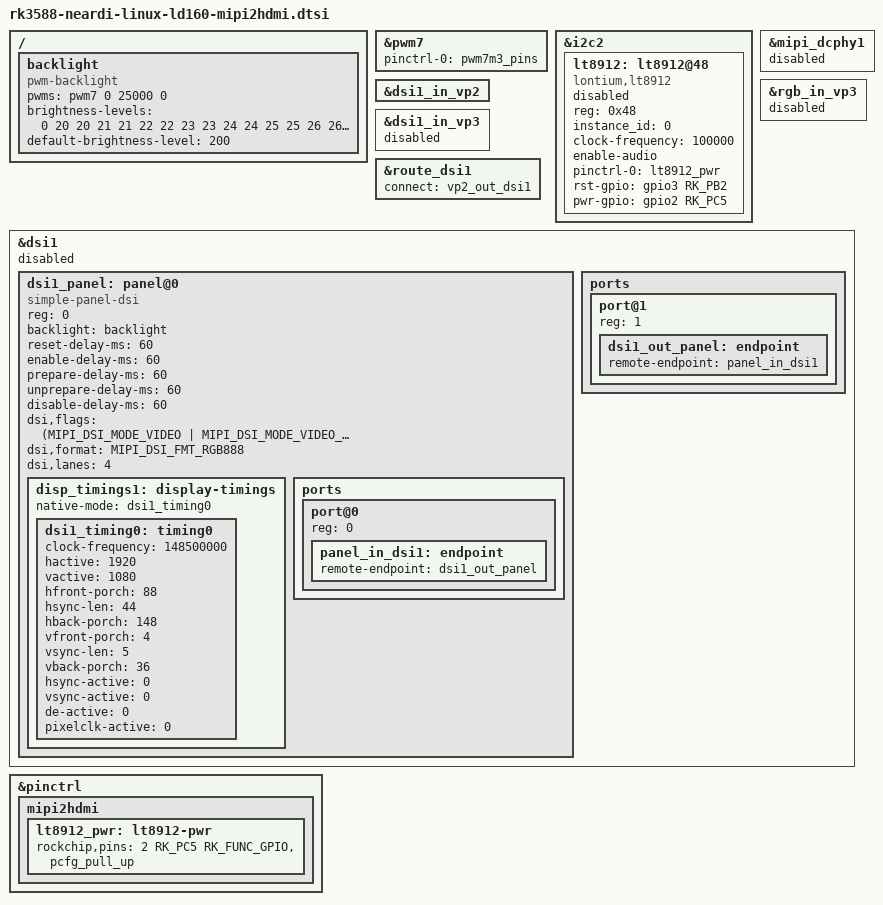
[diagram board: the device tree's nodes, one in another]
// SPDX-License-Identifier: (GPL-2.0+ OR MIT)
/*
 * Copyright (c) 2020 Rockchip Electronics Co., Ltd.
 *
 */
 
/ {
backlight: backlight {
		status="okay";
		compatible = "pwm-backlight";
		pwms = <&pwm7 0 25000 0>;
		brightness-levels = <
			  0  20  20  21  21  22  22  23
			 23  24  24  25  25  26  26  27
			 27  28  28  29  29  30  30  31
			 31  32  32  33  33  34  34  35
			 35  36  36  37  37  38  38  39
			 40  41  42  43  44  45  46  47
			 48  49  50  51  52  53  54  55
			 56  57  58  59  60  61  62  63
			 64  65  66  67  68  69  70  71
			 72  73  74  75  76  77  78  79
			 80  81  82  83  84  85  86  87
			 88  89  90  91  92  93  94  95
			 96  97  98  99 100 101 102 103
			104 105 106 107 108 109 110 111
			112 113 114 115 116 117 118 119
			120 121 122 123 124 125 126 127
			128 129 130 131 132 133 134 135
			136 137 138 139 140 141 142 143
			144 145 146 147 148 149 150 151
			152 153 154 155 156 157 158 159
			160 161 162 163 164 165 166 167
			168 169 170 171 172 173 174 175
			176 177 178 179 180 181 182 183
			184 185 186 187 188 189 190 191
			192 193 194 195 196 197 198 199
			200 201 202 203 204 205 206 207
			208 209 210 211 212 213 214 215
			216 217 218 219 220 221 222 223
			224 225 226 227 228 229 230 231
			232 233 234 235 236 237 238 239
			240 241 242 243 244 245 246 247
			248 249 250 251 252 253 254 255
		>;
		default-brightness-level = <200>;
	};

};

&pwm7{
        status = "okay";
		pinctrl-names = "active";
        pinctrl-0 = <&pwm7m3_pins>;
};

&i2c2 {
	status = "okay";
	
	lt8912:lt8912@48{
		status = "disabled";
		compatible = "lontium,lt8912";
		reg = <0x48>;
		instance_id = <0>;
		clock-frequency = <100000>;
		enable-audio;
		
		pinctrl-names = "default";
		pinctrl-0 = <&lt8912_pwr>;

		//irq-gpio = <&gpio2 RK_PC5 IRQ_TYPE_EDGE_BOTH>;
		rst-gpio = <&gpio3 RK_PB2 GPIO_ACTIVE_HIGH>; //106
		pwr-gpio = <&gpio2 RK_PC5 GPIO_ACTIVE_HIGH>; //85
	};
	};
	
	
/*
 * mipi_dcphy1 needs to be enabled
 * when dsi1 is enabled
 */
 &mipi_dcphy1{
	status = "disabled";
 };

&dsi1_in_vp2 {
	status = "okay";
};

&rgb_in_vp3{
status = "disabled";
};

&dsi1_in_vp3 {
	status = "disabled";
};


&route_dsi1 {
	status = "okay";
	connect = <&vp2_out_dsi1>;
};


&dsi1 {   
	status = "disabled";             //by lt8912 
	//force-output;
	//rockchip,lane-rate = <400>;
	dsi1_panel: panel@0 {
		status = "okay";
		compatible = "simple-panel-dsi";
		reg = <0>;
		backlight = <&backlight>;
		reset-delay-ms = <60>;
		enable-delay-ms = <60>;
		prepare-delay-ms = <60>;
		unprepare-delay-ms = <60>;
		disable-delay-ms = <60>;
		//force-output;
		dsi,flags =  <(MIPI_DSI_MODE_VIDEO | MIPI_DSI_MODE_VIDEO_BURST |
			MIPI_DSI_MODE_VIDEO_HBP | MIPI_DSI_MODE_LPM |MIPI_DSI_MODE_EOT_PACKET)>;
			
		dsi,format = <MIPI_DSI_FMT_RGB888>;
		dsi,lanes  = <4>;
		
		disp_timings1: display-timings {
			native-mode = <&dsi1_timing0>;
			dsi1_timing0: timing0 {		
			//720p
			/*
				clock-frequency = <74250000>;
				hactive = <1280>;
				vactive = <720>;
				hfront-porch = <110>;
				hsync-len = <40>;
				hback-porch = <220>;
				vfront-porch = <5>;
				vsync-len = <5>;
				vback-porch = <20>;
				hsync-active = <0>;
				vsync-active = <0>;
				de-active = <0>;
				pixelclk-active = <0>;
				*/
				
				//1080p
				
				clock-frequency = <148500000>;
				hactive = <1920>;
				vactive = <1080>;
				
				hfront-porch = <88>;
				hsync-len = <44>;
				hback-porch = <148>;

				vfront-porch = <4>;
				vsync-len = <5>;
				vback-porch = <36>;
				
				hsync-active = <0>;
				vsync-active = <0>;
				de-active = <0>;
				pixelclk-active = <0>;
				
			};
		};

		ports {
			#address-cells = <1>;
			#size-cells = <0>;

			port@0 {
				reg = <0>;
				panel_in_dsi1: endpoint {
					remote-endpoint = <&dsi1_out_panel>;
				};
			};
		};
	};

	ports {
		#address-cells = <1>;
		#size-cells = <0>;

		port@1 {
			reg = <1>;
			dsi1_out_panel: endpoint {
				remote-endpoint = <&panel_in_dsi1>;
			};
		};
	};

};
&pinctrl {
	mipi2hdmi {
		lt8912_pwr: lt8912-pwr {
			rockchip,pins =
				/* lt8912 power en */
				<2 RK_PC5 RK_FUNC_GPIO &pcfg_pull_up>;
		};
	};
};

